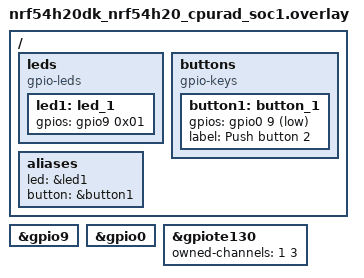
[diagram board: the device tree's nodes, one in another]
/*
 * Copyright (c) 2023 Nordic Semiconductor ASA
 *
 * SPDX-License-Identifier: Apache-2.0
 */

 / {
	leds {
		compatible = "gpio-leds";
		led1: led_1 {
			gpios = < &gpio9 0x01 GPIO_ACTIVE_HIGH >;
		};
	};

	buttons {
		compatible = "gpio-keys";
		button1: button_1 {
			gpios = <&gpio0 9 (GPIO_PULL_UP | GPIO_ACTIVE_LOW)>;
			label = "Push button 2";
		};

	};

	aliases {
		led = &led1;
		button = &button1;
	};
};

&gpio9 {
	status = "okay";
};

&gpio0 {
	status = "okay";
};

&gpiote130 {
	owned-channels = <1 3>;
	status = "okay";
};
